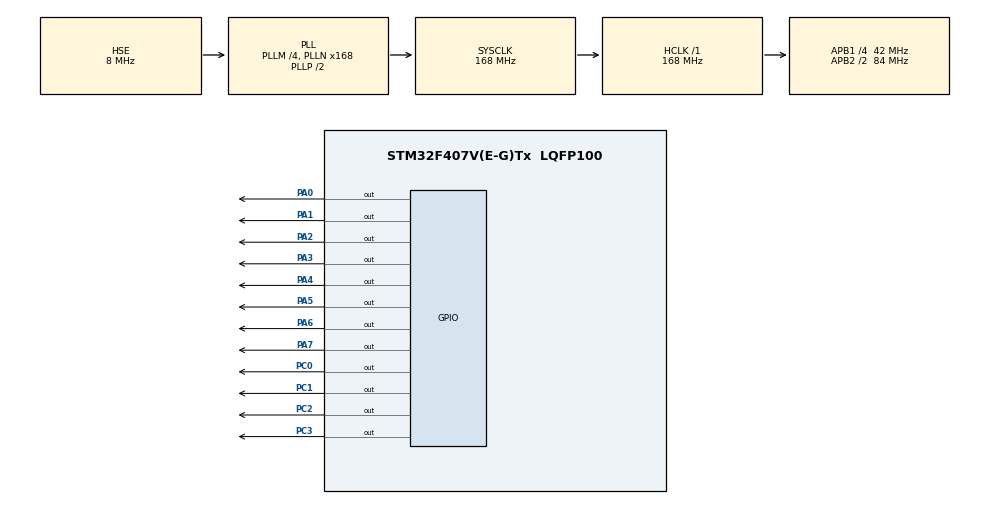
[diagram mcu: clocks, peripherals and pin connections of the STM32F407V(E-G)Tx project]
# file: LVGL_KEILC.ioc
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Mcu.Family=STM32F4
Mcu.Name=STM32F407V(E-G)Tx
Mcu.Package=LQFP100
NVIC.PriorityGroup=NVIC_PRIORITYGROUP_4
PA0-WKUP.GPIO_Speed=GPIO_SPEED_FREQ_VERY_HIGH
PA0-WKUP.Signal=GPIO_Output
PA1.GPIO_Speed=GPIO_SPEED_FREQ_VERY_HIGH
PA1.Signal=GPIO_Output
PA13.Mode=Serial_Wire
PA13.Signal=SYS_JTMS-SWDIO
PA14.Mode=Serial_Wire
PA14.Signal=SYS_JTCK-SWCLK
PA2.GPIO_Speed=GPIO_SPEED_FREQ_VERY_HIGH
PA2.Signal=GPIO_Output
PA3.GPIO_Speed=GPIO_SPEED_FREQ_VERY_HIGH
PA3.Signal=GPIO_Output
PA4.GPIO_Speed=GPIO_SPEED_FREQ_VERY_HIGH
PA4.Signal=GPIO_Output
PA5.GPIO_Speed=GPIO_SPEED_FREQ_VERY_HIGH
PA5.Signal=GPIO_Output
PA6.GPIO_Speed=GPIO_SPEED_FREQ_VERY_HIGH
PA6.Signal=GPIO_Output
PA7.GPIO_Speed=GPIO_SPEED_FREQ_VERY_HIGH
PA7.Signal=GPIO_Output
PC0.GPIO_Speed=GPIO_SPEED_FREQ_VERY_HIGH
PC0.Signal=GPIO_Output
PC1.GPIO_Speed=GPIO_SPEED_FREQ_VERY_HIGH
PC1.Signal=GPIO_Output
PC2.GPIO_Speed=GPIO_SPEED_FREQ_VERY_HIGH
PC2.Signal=GPIO_Output
PC3.GPIO_Speed=GPIO_SPEED_FREQ_VERY_HIGH
PC3.Signal=GPIO_Output
PH0-OSC_IN.Mode=HSE-External-Oscillator
PH0-OSC_IN.Signal=RCC_OSC_IN
PH1-OSC_OUT.Mode=HSE-External-Oscillator
PH1-OSC_OUT.Signal=RCC_OSC_OUT
ProjectManager.HeapSize=0x200
ProjectManager.StackSize=0x400
ProjectManager.TargetToolchain=MDK-ARM V5.32
RCC.48MHZClocksFreq_Value=84000000
RCC.AHBFreq_Value=168000000
RCC.APB1CLKDivider=RCC_HCLK_DIV4
RCC.APB1Freq_Value=42000000
RCC.APB1TimFreq_Value=84000000
RCC.APB2CLKDivider=RCC_HCLK_DIV2
RCC.APB2Freq_Value=84000000
RCC.APB2TimFreq_Value=168000000
RCC.CortexFreq_Value=168000000
RCC.HCLKFreq_Value=168000000
RCC.HSE_VALUE=8000000
RCC.HSI_VALUE=16000000
RCC.LSE_VALUE=32768
RCC.PLLM=4
RCC.PLLN=168
RCC.PLLSourceVirtual=RCC_PLLSOURCE_HSE
RCC.SYSCLKFreq_VALUE=168000000
RCC.SYSCLKSource=RCC_SYSCLKSOURCE_PLLCLK
RCC.VCOOutputFreq_Value=336000000
TIM1.Period=0xffff-1
TIM1.Prescaler=72-1
VP_TIM1_VS_ClockSourceINT.Mode=Internal
board=custom

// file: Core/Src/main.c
/* USER CODE BEGIN Header */
/**
  ******************************************************************************
  * @file           : main.c
  * @brief          : Main program body
  ******************************************************************************
  * @attention
  *
  * Copyright (c) 2023 STMicroelectronics.
  * All rights reserved.
  *
  * This software is licensed under terms that can be found in the LICENSE file
  * in the root directory of this software component.
  * If no LICENSE file comes with this software, it is provided AS-IS.
  *
  ******************************************************************************
  */
/* USER CODE END Header */
#include "main.h"

/* USER CODE BEGIN Includes */
#include "lvgl.h"
#include "../lvgl/examples/lv_examples.h"
#include "lcd_lvgl.h"
#include "stdio.h"

/* USER CODE END Includes */

TIM_HandleTypeDef htim1;

void SystemClock_Config(void);
static void MX_GPIO_Init(void);
static void MX_TIM1_Init(void);

int main(void)
{

  /* MCU Configuration--------------------------------------------------------*/

  /* Reset of all peripherals, Initializes the Flash interface and the Systick. */
  HAL_Init();

  /* Configure the system clock */
  SystemClock_Config();

  /* Initialize all configured peripherals */
  MX_GPIO_Init();
  MX_TIM1_Init();

  /* Infinite loop */
  while (1)
  {

  }
}

void SystemClock_Config(void)
{
  RCC_OscInitTypeDef RCC_OscInitStruct = {0};
  RCC_ClkInitTypeDef RCC_ClkInitStruct = {0};

  /** Configure the main internal regulator output voltage
  */
  __HAL_RCC_PWR_CLK_ENABLE();
  __HAL_PWR_VOLTAGESCALING_CONFIG(PWR_REGULATOR_VOLTAGE_SCALE1);

  /** Initializes the RCC Oscillators according to the specified parameters
  * in the RCC_OscInitTypeDef structure.
  */
  RCC_OscInitStruct.OscillatorType = RCC_OSCILLATORTYPE_HSE;
  RCC_OscInitStruct.HSEState = RCC_HSE_ON;
  RCC_OscInitStruct.PLL.PLLState = RCC_PLL_ON;
  RCC_OscInitStruct.PLL.PLLSource = RCC_PLLSOURCE_HSE;
  RCC_OscInitStruct.PLL.PLLM = 4;
  RCC_OscInitStruct.PLL.PLLN = 168;
  RCC_OscInitStruct.PLL.PLLP = RCC_PLLP_DIV2;
  RCC_OscInitStruct.PLL.PLLQ = 4;
  if (HAL_RCC_OscConfig(&RCC_OscInitStruct) != HAL_OK)
  {
    Error_Handler();
  }

  /** Initializes the CPU, AHB and APB buses clocks
  */
  RCC_ClkInitStruct.ClockType = RCC_CLOCKTYPE_HCLK|RCC_CLOCKTYPE_SYSCLK
                              |RCC_CLOCKTYPE_PCLK1|RCC_CLOCKTYPE_PCLK2;
  RCC_ClkInitStruct.SYSCLKSource = RCC_SYSCLKSOURCE_PLLCLK;
  RCC_ClkInitStruct.AHBCLKDivider = RCC_SYSCLK_DIV1;
  RCC_ClkInitStruct.APB1CLKDivider = RCC_HCLK_DIV4;
  RCC_ClkInitStruct.APB2CLKDivider = RCC_HCLK_DIV2;

  if (HAL_RCC_ClockConfig(&RCC_ClkInitStruct, FLASH_LATENCY_5) != HAL_OK)
  {
    Error_Handler();
  }
}

static void MX_TIM1_Init(void)
{

  TIM_ClockConfigTypeDef sClockSourceConfig = {0};
  TIM_MasterConfigTypeDef sMasterConfig = {0};

  htim1.Instance = TIM1;
  htim1.Init.Prescaler = 72-1;
  htim1.Init.CounterMode = TIM_COUNTERMODE_UP;
  htim1.Init.Period = 0xffff-1;
  htim1.Init.ClockDivision = TIM_CLOCKDIVISION_DIV1;
  htim1.Init.RepetitionCounter = 0;
  htim1.Init.AutoReloadPreload = TIM_AUTORELOAD_PRELOAD_DISABLE;
  if (HAL_TIM_Base_Init(&htim1) != HAL_OK)
  {
    Error_Handler();
  }
  sClockSourceConfig.ClockSource = TIM_CLOCKSOURCE_INTERNAL;
  if (HAL_TIM_ConfigClockSource(&htim1, &sClockSourceConfig) != HAL_OK)
  {
    Error_Handler();
  }
  sMasterConfig.MasterOutputTrigger = TIM_TRGO_RESET;
  sMasterConfig.MasterSlaveMode = TIM_MASTERSLAVEMODE_DISABLE;
  if (HAL_TIMEx_MasterConfigSynchronization(&htim1, &sMasterConfig) != HAL_OK)
  {
    Error_Handler();
  }

}

static void MX_GPIO_Init(void)
{
  GPIO_InitTypeDef GPIO_InitStruct = {0};

  /* GPIO Ports Clock Enable */
  __HAL_RCC_GPIOH_CLK_ENABLE();
  __HAL_RCC_GPIOC_CLK_ENABLE();
  __HAL_RCC_GPIOA_CLK_ENABLE();

  /*Configure GPIO pin Output Level */
  HAL_GPIO_WritePin(GPIOC, GPIO_PIN_0|GPIO_PIN_1|GPIO_PIN_2|GPIO_PIN_3, GPIO_PIN_RESET);

  /*Configure GPIO pin Output Level */
  HAL_GPIO_WritePin(GPIOA, GPIO_PIN_0|GPIO_PIN_1|GPIO_PIN_2|GPIO_PIN_3
                          |GPIO_PIN_4|GPIO_PIN_5|GPIO_PIN_6|GPIO_PIN_7, GPIO_PIN_RESET);

  /*Configure GPIO pins : PC0 PC1 PC2 PC3 */
  GPIO_InitStruct.Pin = GPIO_PIN_0|GPIO_PIN_1|GPIO_PIN_2|GPIO_PIN_3;
  GPIO_InitStruct.Mode = GPIO_MODE_OUTPUT_PP;
  GPIO_InitStruct.Pull = GPIO_NOPULL;
  GPIO_InitStruct.Speed = GPIO_SPEED_FREQ_VERY_HIGH;
  HAL_GPIO_Init(GPIOC, &GPIO_InitStruct);

  /*Configure GPIO pins : PA0 PA1 PA2 PA3
                           PA4 PA5 PA6 PA7 */
  GPIO_InitStruct.Pin = GPIO_PIN_0|GPIO_PIN_1|GPIO_PIN_2|GPIO_PIN_3
                          |GPIO_PIN_4|GPIO_PIN_5|GPIO_PIN_6|GPIO_PIN_7;
  GPIO_InitStruct.Mode = GPIO_MODE_OUTPUT_PP;
  GPIO_InitStruct.Pull = GPIO_NOPULL;
  GPIO_InitStruct.Speed = GPIO_SPEED_FREQ_VERY_HIGH;
  HAL_GPIO_Init(GPIOA, &GPIO_InitStruct);

}

void Error_Handler(void)
{
  __disable_irq();
  while (1)
  {
  }
}
